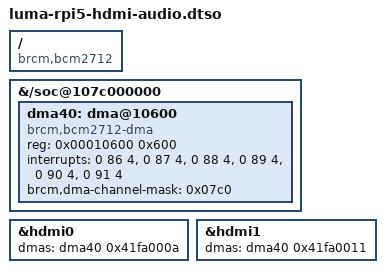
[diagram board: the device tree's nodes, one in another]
// SPDX-License-Identifier: GPL-2.0
/*
 * HDMI audio for BCM2712 boards (Raspberry Pi 5, Pi 500, CM5) on mainline
 * device trees: the 40-bit DMA controller (channels 6-10) and the HDMI MAI
 * DMA requests of C1 silicon; luma-rpi5-hdmi-audio-d0.dtso then moves the
 * requests to the D0 lines. The node and request cells follow Raspberry Pi's
 * bcm2712-ds.dtsi and bcm2712-rpi.dtsi (raspberrypi/linux rpi-7.2.y).
 *
 * Needs the bcm2712-dma driver and the BCM2712 vc4 HDMI audio address fix
 * (luma-rpi5-kmod). Without the DMA driver vc4 HDMI waits for the
 * controller and the display stays on the firmware framebuffer.
 */
/dts-v1/;
/plugin/;

/ {
	compatible = "brcm,bcm2712";

	fragment@0 {
		target-path = "/soc@107c000000";
		__overlay__ {
			dma40: dma@10600 {
				compatible = "brcm,bcm2712-dma";
				reg = <0x00010600 0x600>;
				interrupts = <0 86 4>, <0 87 4>, <0 88 4>,
					     <0 89 4>, <0 90 4>, <0 91 4>;
				interrupt-names = "dma6", "dma7", "dma8",
						  "dma9", "dma10", "dma11";
				#dma-cells = <1>;
				/* Channel 11 belongs to the VPU firmware (VCHIQ). */
				brcm,dma-channel-mask = <0x07c0>;
			};
		};
	};

	/*
	 * C1: DREQ 10 (HDMI0 MAI) and 17 (HDMI1 MAI) with multi-beat burst
	 * (bit 30), wide source (bit 24), QoS 10 and panic QoS 15.
	 */
	fragment@1 {
		target = <&hdmi0>;
		__overlay__ {
			dmas = <&dma40 0x41fa000a>;
			dma-names = "audio-rx";
		};
	};

	fragment@2 {
		target = <&hdmi1>;
		__overlay__ {
			dmas = <&dma40 0x41fa0011>;
			dma-names = "audio-rx";
		};
	};
};
